# LPC11U6x register map
File version: 0.8
CPU: CM0PLUS r0p1, little endian, no MPU, no FPU, 2 interrupt priority bits
Registers are 32-bit, read-write, reset 0x0 unless marked. A register's access mark holds for its fields unless they carry their own. Offsets are from the block's base; [hi:lo] are bit positions; {n}, {i} and the like mark numbered series; 'fields as' and 'values as' point back to an identical list.

## FLASHCTRL — Flash controller
Base 0x4003C000
0x10 FLASHCFG reset not defined — Flash configuration register
  [1:0] FLASHTIM — Flash memory access time. FLASHTIM +1 is equal to the number of system clocks used for flash access.
    0=1_SYSTEM_CLOCK_FLASH (1 system clock flash access time (for system clock frequencies of up to 20 MHz).); 1=2_SYSTEM_CLOCKS_FLASH (2 system clocks flash access time (for system clock frequencies of up to 30 MHz).)
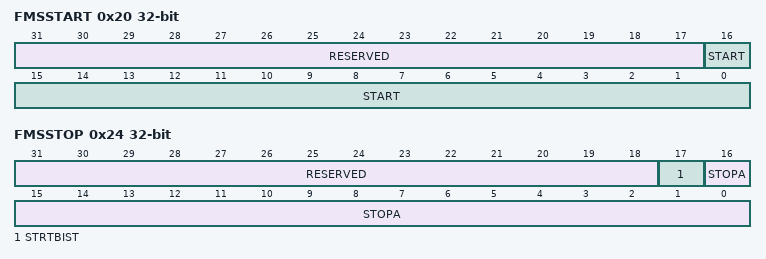
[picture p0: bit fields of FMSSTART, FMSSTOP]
0x20 FMSSTART — Signature start address register
  [31:17] RESERVED — Reserved, user software should not write ones to reserved bits. The value read from a reserved bit is not defined.
  [16:0] START — Signature generation start address (corresponds to AHB byte address bits[20:4]).
0x24 FMSSTOP — Signature stop-address register
  [31:18] RESERVED — Reserved, user software should not write ones to reserved bits. The value read from a reserved bit is not defined.
  [17] STRTBIST — When this bit is written to 1, signature generation starts. At the end of signature generation, this bit is automatically cleared.
  [16:0] STOPA — Stop address for signature generation (the word specified by STOPA is included in the address range). The address is in units of memory words, not bytes. If the option bistprotection=1, bits 2:0 cannot be written and are forced to 111.
0x2C FMSW0 ro reset not defined — Signature Word
  [31:0] SIG — 32-bit signature.

## IOCON — I/O control (IOCON)
Base 0x40044000
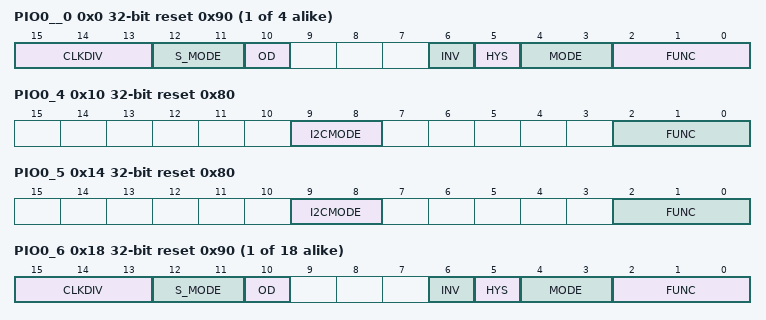
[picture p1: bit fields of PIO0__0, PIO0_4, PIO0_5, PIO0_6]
{0x0+4i} PIO0__{i} (i=0..3) reset 0x90 — I/O configuration for port PIO0
  [15:13] CLKDIV — Select peripheral clock divider for input filter sampling clock IOCONCLKDIV. Value 0x7 is reserved.
    0=IOCONCLKDIV0 (IOCONCLKDIV0. Use IOCON clock divider 0.); 1=IOCONCLKDIV1 (IOCONCLKDIV1. Use IOCON clock divider 1.); 2=IOCONCLKDIV2 (IOCONCLKDIV2 Use IOCON clock divider 2.); {v}=IOCONCLKDIV{v} (IOCONCLKDIV{v}. Use IOCON clock divider {v}.) (v=3..6)
  [12:11] S_MODE — Digital filter sample mode.
    0=BYPASS_INPUT_FILTER; 1=1_CLOCK_CYCLE (1 clock cycle. Input pulses shorter than one filter clock are rejected.); 2=2_CLOCK_CYCLES (2 clock cycles. Input pulses shorter than two filter clocks are rejected.); 3=3_CLOCK_CYCLES (3 clock cycles. Input pulses shorter than three filter clocks are rejected.)
  [10] OD — Open-drain mode.
    0=DISABLE; 1=ENABLE (Enable. Open-drain mode enabled. This is not a true open-drain mode.)
  [6] INV — Invert input
    0=INPUT_NOT_INVERTED (Input not inverted (HIGH on pin reads as 1; LOW on pin reads as 0).); 1=INPUT_INVERTED_HIGH (Input inverted (HIGH on pin reads as 0, LOW on pin reads as 1).)
  [5] HYS — Hysteresis.
    0=DISABLE; 1=ENABLE
  [4:3] MODE — Selects function mode (on-chip pull-up/pull-down resistor control).
    0=INACTIVE_NO_PULL_DO (Inactive (no pull-down/pull-up resistor enabled).); 1=PULL_DOWN_RESISTOR_E (Pull-down resistor enabled.); 2=PULL_UP_RESISTOR_ENA (Pull-up resistor enabled.); 3=REPEATER_MODE
  [2:0] FUNC — Selects pin function.
0x10 PIO0_4 reset 0x80 — I/O configuration for open-drain pin PIO0_4
  [9:8] I2CMODE — Selects I2C mode (see Section 7.3.8). Select Standard mode (I2CMODE = 00, default) or Standard I/O functionality (I2CMODE = 01) if the pin function is GPIO (FUNC = 000).
    0=STANDARD_MODE_FAST (Standard mode/ Fast-mode I2C.); 1=STANDARD_IO_FUNCTIO (Standard I/O functionality); 2=FAST_MODE_PLUS_I2C
  [2:0] FUNC — Selects pin function.
0x14 PIO0_5 reset 0x80 — I/O configuration for open-drain pin PIO0_5
  fields as PIO0_4
{0x0+4i} PIO0_{i} (i=6..23) reset 0x90 — I/O configuration for port PIO0
  fields as PIO0__0
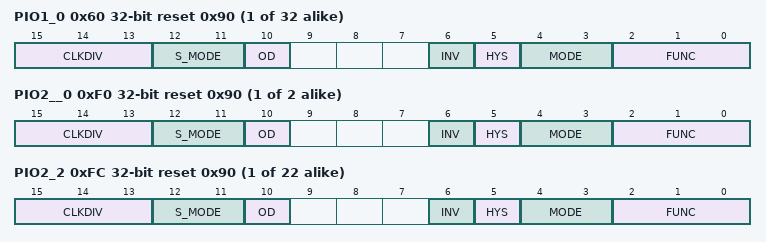
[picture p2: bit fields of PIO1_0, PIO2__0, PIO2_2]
{0x60+4i} PIO1_{i} (i=0..31) reset 0x90 — I/O configuration for port PIO1
  [15:13] CLKDIV — Select peripheral clock divider for input filter sampling clock IOCONCLKDIV. Value 0x7 is reserved.
    values as PIO0__0.CLKDIV
  [12:11] S_MODE — Digital filter sample mode.
    values as PIO0__0.S_MODE
  [10] OD — Open-drain mode.
    0=DISABLE; 1=ENABLED (Enabled. Open-drain mode enabled. This is not a true open-drain mode.)
  [6] INV — Invert input
    values as PIO0__0.INV
  [5] HYS — Hysteresis.
    0=DISABLE; 1=ENABLE
  [4:3] MODE — Selects function mode (on-chip pull-up/pull-down resistor control).
    values as PIO0__0.MODE
  [2:0] FUNC — Selects pin function.
{0xF0+4i} PIO2__{i} (i=0..1) reset 0x90 — I/O configuration for port PIO2
  fields as PIO1_0
{0xF4+4i} PIO2_{i} (i=2..23) reset 0x90 — I/O configuration for port PIO2
  fields as PIO1_0
